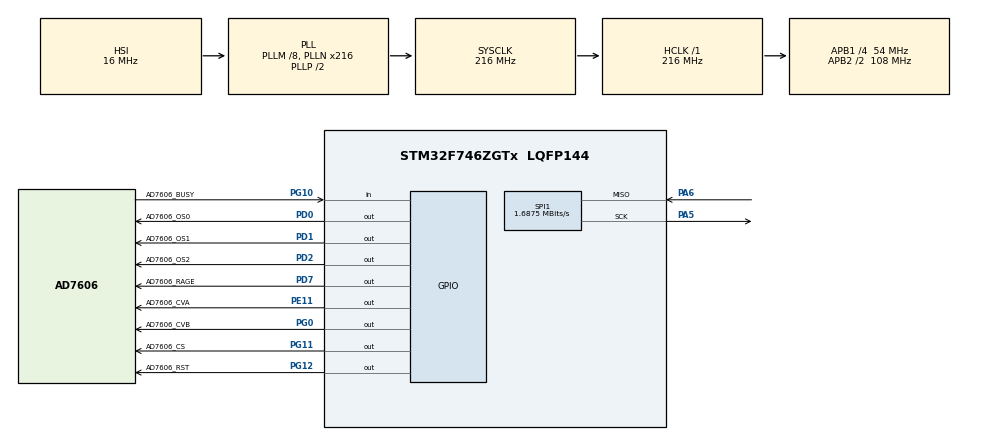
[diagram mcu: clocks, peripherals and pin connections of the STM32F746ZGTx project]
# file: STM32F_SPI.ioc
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Mcu.Family=STM32F7
Mcu.Name=STM32F746ZGTx
Mcu.Package=LQFP144
NVIC.PriorityGroup=NVIC_PRIORITYGROUP_4
NVIC.TIM6_DAC_IRQn=true\:0\:0\:false\:false\:true\:true
PA5.Mode=RX_Only_Simplex_Unidirect_Master
PA5.Signal=SPI1_SCK
PA6.Mode=RX_Only_Simplex_Unidirect_Master
PA6.Signal=SPI1_MISO
PD0.GPIO_Label=AD7606_OS0
PD0.Signal=GPIO_Output
PD1.GPIO_Label=AD7606_OS1
PD1.Signal=GPIO_Output
PD2.GPIO_Label=AD7606_OS2
PD2.Signal=GPIO_Output
PD7.GPIO_Label=AD7606_RAGE
PD7.Signal=GPIO_Output
PE11.GPIO_Label=AD7606_CVA
PE11.Signal=GPIO_Output
PG0.GPIO_Label=AD7606_CVB
PG0.Signal=GPIO_Output
PG10.GPIO_Label=AD7606_BUSY
PG10.Signal=GPIO_Input
PG11.GPIO_Label=AD7606_CS
PG11.Signal=GPIO_Output
PG12.GPIO_Label=AD7606_RST
PG12.Signal=GPIO_Output
ProjectManager.HeapSize=0x200
ProjectManager.StackSize=0x400
ProjectManager.TargetToolchain=EWARM
RCC.AHBFreq_Value=216000000
RCC.APB1CLKDivider=RCC_HCLK_DIV4
RCC.APB1Freq_Value=54000000
RCC.APB1TimFreq_Value=108000000
RCC.APB2CLKDivider=RCC_HCLK_DIV2
RCC.APB2Freq_Value=108000000
RCC.APB2TimFreq_Value=216000000
RCC.CortexFreq_Value=216000000
RCC.HCLKFreq_Value=216000000
RCC.HSE_VALUE=25000000
RCC.HSI_VALUE=16000000
RCC.LSE_VALUE=32768
RCC.PLLM=8
RCC.PLLN=216
RCC.SYSCLKFreq_VALUE=216000000
RCC.SYSCLKSource=RCC_SYSCLKSOURCE_PLLCLK
RCC.USBFreq_Value=216000000
RCC.VCOOutputFreq_Value=432000000
SPI1.BaudRatePrescaler=SPI_BAUDRATEPRESCALER_64
SPI1.CLKPolarity=SPI_POLARITY_HIGH
SPI1.CalculateBaudRate=1.6875 MBits/s
SPI1.DataSize=SPI_DATASIZE_8BIT
SPI1.Direction=SPI_DIRECTION_2LINES_RXONLY
SPI1.Mode=SPI_MODE_MASTER
SPI1.VirtualType=VM_MASTER
TIM6.Period=100-1
TIM6.Prescaler=21600-1
VP_TIM6_VS_ClockSourceINT.Mode=Enable_Timer
board=STM32F_SPI

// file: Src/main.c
/**
  ******************************************************************************
  * @file           : main.c
  * @brief          : Main program body
  ******************************************************************************
  ** This notice applies to any and all portions of this file
  * that are not between comment pairs USER CODE BEGIN and
  * USER CODE END. Other portions of this file, whether
  * inserted by the user or by software development tools
  * are owned by their respective copyright owners.
  *
  * COPYRIGHT(c) 2020 STMicroelectronics
  *
  * Redistribution and use in source and binary forms, with or without modification,
  * are permitted provided that the following conditions are met:
  *   1. Redistributions of source code must retain the above copyright notice,
  *      this list of conditions and the following disclaimer.
  *   2. Redistributions in binary form must reproduce the above copyright notice,
  *      this list of conditions and the following disclaimer in the documentation
  *      and/or other materials provided with the distribution.
  *   3. Neither the name of STMicroelectronics nor the names of its contributors
  *      may be used to endorse or promote products derived from this software
  *      without specific prior written permission.
  *
  * THIS SOFTWARE IS PROVIDED BY THE COPYRIGHT HOLDERS AND CONTRIBUTORS "AS IS"
  * AND ANY EXPRESS OR IMPLIED WARRANTIES, INCLUDING, BUT NOT LIMITED TO, THE
  * IMPLIED WARRANTIES OF MERCHANTABILITY AND FITNESS FOR A PARTICULAR PURPOSE ARE
  * DISCLAIMED. IN NO EVENT SHALL THE COPYRIGHT HOLDER OR CONTRIBUTORS BE LIABLE
  * FOR ANY DIRECT, INDIRECT, INCIDENTAL, SPECIAL, EXEMPLARY, OR CONSEQUENTIAL
  * DAMAGES (INCLUDING, BUT NOT LIMITED TO, PROCUREMENT OF SUBSTITUTE GOODS OR
  * SERVICES; LOSS OF USE, DATA, OR PROFITS; OR BUSINESS INTERRUPTION) HOWEVER
  * CAUSED AND ON ANY THEORY OF LIABILITY, WHETHER IN CONTRACT, STRICT LIABILITY,
  * OR TORT (INCLUDING NEGLIGENCE OR OTHERWISE) ARISING IN ANY WAY OUT OF THE USE
  * OF THIS SOFTWARE, EVEN IF ADVISED OF THE POSSIBILITY OF SUCH DAMAGE.
  *
  ******************************************************************************
  */
#include "main.h"
#include "stm32f7xx_hal.h"

/* USER CODE BEGIN Includes */
#include "AD7606.h"
/* USER CODE END Includes */

SPI_HandleTypeDef hspi1;

TIM_HandleTypeDef htim6;

/* USER CODE BEGIN PV */
/* Private variables ---------------------------------------------------------*/

int main_cnt = 0;

/* USER CODE END PV */

void SystemClock_Config(void);
static void MX_GPIO_Init(void);
static void MX_SPI1_Init(void);
static void MX_TIM6_Init(void);

/* USER CODE BEGIN PFP */
/* Private function prototypes -----------------------------------------------*/

/* USER CODE END PFP */

int main(void)
{

  /* MCU Configuration----------------------------------------------------------*/

  /* Reset of all peripherals, Initializes the Flash interface and the Systick. */
  HAL_Init();

  /* Configure the system clock */
  SystemClock_Config();

  /* Initialize all configured peripherals */
  MX_GPIO_Init();
  MX_SPI1_Init();
  MX_TIM6_Init();
  /* USER CODE BEGIN 2 */
  AD7606_VoltageRange_Setting(10);                      // AD7606 Output Voltage Setting 10V
  AD7606_OverSampling_Setting(4);                       // AD7606 Sampling Setting
  AD7606_Reset();                                       // AD7606 Reset

  HAL_Delay(5);

  HAL_TIM_Base_Start_IT(&htim6);                        // TIM6 Count Interrupt Enable
  /* USER CODE END 2 */

  /* Infinite loop */
  /* USER CODE BEGIN WHILE */
  while (1)
  {
    main_cnt++;
  /* USER CODE END WHILE */

  }

}

void SystemClock_Config(void)
{

  RCC_OscInitTypeDef RCC_OscInitStruct;
  RCC_ClkInitTypeDef RCC_ClkInitStruct;

    /**Configure the main internal regulator output voltage
    */
  __HAL_RCC_PWR_CLK_ENABLE();

  __HAL_PWR_VOLTAGESCALING_CONFIG(PWR_REGULATOR_VOLTAGE_SCALE1);

    /**Initializes the CPU, AHB and APB busses clocks
    */
  RCC_OscInitStruct.OscillatorType = RCC_OSCILLATORTYPE_HSI;
  RCC_OscInitStruct.HSIState = RCC_HSI_ON;
  RCC_OscInitStruct.HSICalibrationValue = 16;
  RCC_OscInitStruct.PLL.PLLState = RCC_PLL_ON;
  RCC_OscInitStruct.PLL.PLLSource = RCC_PLLSOURCE_HSI;
  RCC_OscInitStruct.PLL.PLLM = 8;
  RCC_OscInitStruct.PLL.PLLN = 216;
  RCC_OscInitStruct.PLL.PLLP = RCC_PLLP_DIV2;
  RCC_OscInitStruct.PLL.PLLQ = 2;
  if (HAL_RCC_OscConfig(&RCC_OscInitStruct) != HAL_OK)
  {
    _Error_Handler(__FILE__, __LINE__);
  }

    /**Activate the Over-Drive mode
    */
  if (HAL_PWREx_EnableOverDrive() != HAL_OK)
  {
    _Error_Handler(__FILE__, __LINE__);
  }

    /**Initializes the CPU, AHB and APB busses clocks
    */
  RCC_ClkInitStruct.ClockType = RCC_CLOCKTYPE_HCLK|RCC_CLOCKTYPE_SYSCLK
                              |RCC_CLOCKTYPE_PCLK1|RCC_CLOCKTYPE_PCLK2;
  RCC_ClkInitStruct.SYSCLKSource = RCC_SYSCLKSOURCE_PLLCLK;
  RCC_ClkInitStruct.AHBCLKDivider = RCC_SYSCLK_DIV1;
  RCC_ClkInitStruct.APB1CLKDivider = RCC_HCLK_DIV4;
  RCC_ClkInitStruct.APB2CLKDivider = RCC_HCLK_DIV2;

  if (HAL_RCC_ClockConfig(&RCC_ClkInitStruct, FLASH_LATENCY_7) != HAL_OK)
  {
    _Error_Handler(__FILE__, __LINE__);
  }

    /**Configure the Systick interrupt time
    */
  HAL_SYSTICK_Config(HAL_RCC_GetHCLKFreq()/1000);

    /**Configure the Systick
    */
  HAL_SYSTICK_CLKSourceConfig(SYSTICK_CLKSOURCE_HCLK);

  /* SysTick_IRQn interrupt configuration */
  HAL_NVIC_SetPriority(SysTick_IRQn, 0, 0);
}

/* SPI1 init function */
static void MX_SPI1_Init(void)
{

  /* SPI1 parameter configuration*/
  hspi1.Instance = SPI1;
  hspi1.Init.Mode = SPI_MODE_MASTER;
  hspi1.Init.Direction = SPI_DIRECTION_2LINES_RXONLY;
  hspi1.Init.DataSize = SPI_DATASIZE_8BIT;
  hspi1.Init.CLKPolarity = SPI_POLARITY_HIGH;
  hspi1.Init.CLKPhase = SPI_PHASE_1EDGE;
  hspi1.Init.NSS = SPI_NSS_SOFT;
  hspi1.Init.BaudRatePrescaler = SPI_BAUDRATEPRESCALER_64;
  hspi1.Init.FirstBit = SPI_FIRSTBIT_MSB;
  hspi1.Init.TIMode = SPI_TIMODE_DISABLE;
  hspi1.Init.CRCCalculation = SPI_CRCCALCULATION_DISABLE;
  hspi1.Init.CRCPolynomial = 7;
  hspi1.Init.CRCLength = SPI_CRC_LENGTH_DATASIZE;
  hspi1.Init.NSSPMode = SPI_NSS_PULSE_ENABLE;
  if (HAL_SPI_Init(&hspi1) != HAL_OK)
  {
    _Error_Handler(__FILE__, __LINE__);
  }

}

/* TIM6 init function */
static void MX_TIM6_Init(void)
{

  TIM_MasterConfigTypeDef sMasterConfig;

  htim6.Instance = TIM6;
  htim6.Init.Prescaler = 21600-1;
  htim6.Init.CounterMode = TIM_COUNTERMODE_UP;
  htim6.Init.Period = 100-1;
  htim6.Init.AutoReloadPreload = TIM_AUTORELOAD_PRELOAD_DISABLE;
  if (HAL_TIM_Base_Init(&htim6) != HAL_OK)
  {
    _Error_Handler(__FILE__, __LINE__);
  }

  sMasterConfig.MasterOutputTrigger = TIM_TRGO_RESET;
  sMasterConfig.MasterSlaveMode = TIM_MASTERSLAVEMODE_DISABLE;
  if (HAL_TIMEx_MasterConfigSynchronization(&htim6, &sMasterConfig) != HAL_OK)
  {
    _Error_Handler(__FILE__, __LINE__);
  }

}

/** Configure pins as
        * Analog
        * Input
        * Output
        * EVENT_OUT
        * EXTI
*/
static void MX_GPIO_Init(void)
{

  GPIO_InitTypeDef GPIO_InitStruct;

  /* GPIO Ports Clock Enable */
  __HAL_RCC_GPIOA_CLK_ENABLE();
  __HAL_RCC_GPIOG_CLK_ENABLE();
  __HAL_RCC_GPIOE_CLK_ENABLE();
  __HAL_RCC_GPIOD_CLK_ENABLE();

  /*Configure GPIO pin Output Level */
  HAL_GPIO_WritePin(GPIOG, AD7606_CVB_Pin|AD7606_CS_Pin|AD7606_RST_Pin, GPIO_PIN_RESET);

  /*Configure GPIO pin Output Level */
  HAL_GPIO_WritePin(AD7606_CVA_GPIO_Port, AD7606_CVA_Pin, GPIO_PIN_RESET);

  /*Configure GPIO pin Output Level */
  HAL_GPIO_WritePin(GPIOD, AD7606_OS0_Pin|AD7606_OS1_Pin|AD7606_OS2_Pin|AD7606_RAGE_Pin, GPIO_PIN_RESET);

  /*Configure GPIO pins : AD7606_CVB_Pin AD7606_CS_Pin AD7606_RST_Pin */
  GPIO_InitStruct.Pin = AD7606_CVB_Pin|AD7606_CS_Pin|AD7606_RST_Pin;
  GPIO_InitStruct.Mode = GPIO_MODE_OUTPUT_PP;
  GPIO_InitStruct.Pull = GPIO_NOPULL;
  GPIO_InitStruct.Speed = GPIO_SPEED_FREQ_LOW;
  HAL_GPIO_Init(GPIOG, &GPIO_InitStruct);

  /*Configure GPIO pin : AD7606_CVA_Pin */
  GPIO_InitStruct.Pin = AD7606_CVA_Pin;
  GPIO_InitStruct.Mode = GPIO_MODE_OUTPUT_PP;
  GPIO_InitStruct.Pull = GPIO_NOPULL;
  GPIO_InitStruct.Speed = GPIO_SPEED_FREQ_LOW;
  HAL_GPIO_Init(AD7606_CVA_GPIO_Port, &GPIO_InitStruct);

  /*Configure GPIO pins : AD7606_OS0_Pin AD7606_OS1_Pin AD7606_OS2_Pin AD7606_RAGE_Pin */
  GPIO_InitStruct.Pin = AD7606_OS0_Pin|AD7606_OS1_Pin|AD7606_OS2_Pin|AD7606_RAGE_Pin;
  GPIO_InitStruct.Mode = GPIO_MODE_OUTPUT_PP;
  GPIO_InitStruct.Pull = GPIO_NOPULL;
  GPIO_InitStruct.Speed = GPIO_SPEED_FREQ_LOW;
  HAL_GPIO_Init(GPIOD, &GPIO_InitStruct);

  /*Configure GPIO pin : AD7606_BUSY_Pin */
  GPIO_InitStruct.Pin = AD7606_BUSY_Pin;
  GPIO_InitStruct.Mode = GPIO_MODE_INPUT;
  GPIO_InitStruct.Pull = GPIO_NOPULL;
  HAL_GPIO_Init(AD7606_BUSY_GPIO_Port, &GPIO_InitStruct);

}

void _Error_Handler(char *file, int line)
{
  while(1)
  {
  }
}

/************************ (C) COPYRIGHT STMicroelectronics *****END OF FILE****/
